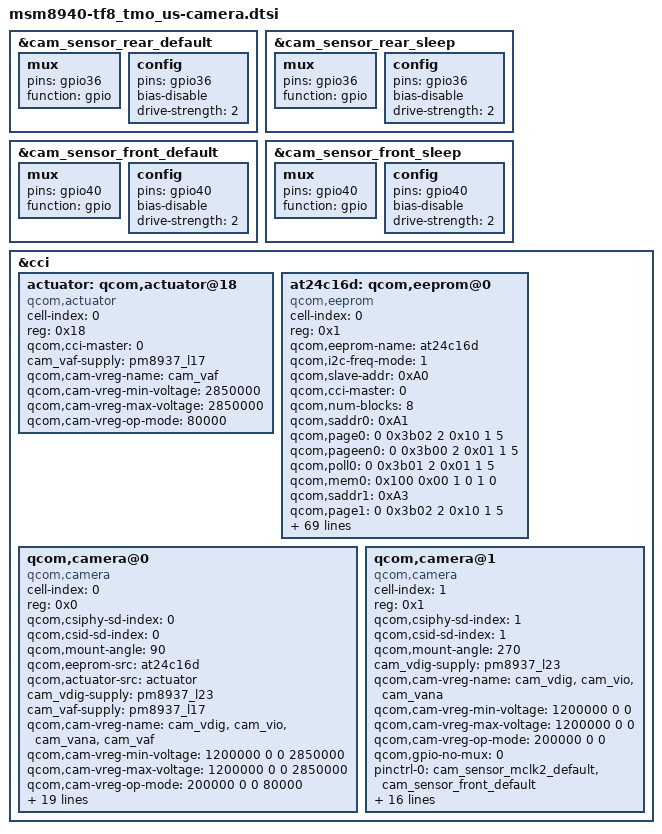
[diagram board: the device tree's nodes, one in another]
/*
 * Copyright (c) 2016, The Linux Foundation. All rights reserved.
 *
 * This program is free software; you can redistribute it and/or modify
 * it under the terms of the GNU General Public License version 2 and
 * only version 2 as published by the Free Software Foundation.
 *
 * This program is distributed in the hope that it will be useful,
 * but WITHOUT ANY WARRANTY; without even the implied warranty of
 * MERCHANTABILITY or FITNESS FOR A PARTICULAR PURPOSE.  See the
 * GNU General Public License for more details.
 */

&cam_sensor_rear_default {
	/* RESET */
	mux {
		pins = "gpio36";
		function = "gpio";
	};

	config {
		pins = "gpio36";
		bias-disable; /* No PULL */
		drive-strength = <2>; /* 2 MA */
	};
};

&cam_sensor_rear_sleep {
	/* RESET */
	mux {
		pins = "gpio36";
		function = "gpio";
	};

	config {
		pins = "gpio36";
		bias-disable; /* No PULL */
		drive-strength = <2>; /* 2 MA */
	};
};

&cam_sensor_front_default {
	/* RESET */
	mux {
		pins = "gpio40";
		function = "gpio";
	};

	config {
		pins = "gpio40";
		bias-disable; /* No PULL */
		drive-strength = <2>; /* 2 MA */
	};
};

&cam_sensor_front_sleep {
	/* RESET */
	mux {
		pins = "gpio40";
		function = "gpio";
	};

	config {
		pins = "gpio40";
		bias-disable; /* No PULL */
		drive-strength = <2>; /* 2 MA */
	};
};

&cci {

	actuator: qcom,actuator@18 {
		cell-index = <0>;
		reg = <0x18>;
		compatible = "qcom,actuator";
		qcom,cci-master = <0>;
		cam_vaf-supply = <&pm8937_l17>;
		qcom,cam-vreg-name = "cam_vaf";
		qcom,cam-vreg-min-voltage = <2850000>;
		qcom,cam-vreg-max-voltage = <2850000>;
		qcom,cam-vreg-op-mode = <80000>;
	};

    at24c16d: qcom,eeprom@0 {
		status = "ok";
		cell-index = <0>;
		reg = <0x1>;
		qcom,eeprom-name = "at24c16d";
		compatible = "qcom,eeprom";
		qcom,i2c-freq-mode = <1>; //fast-mode
		qcom,slave-addr = <0xA0>;
		qcom,cci-master = <0>;
		qcom,num-blocks = <8>;
		qcom,saddr0 = <0xA1>;
		qcom,page0 = <0 0x3b02 2 0x10 1 5>;
		qcom,pageen0 = <0 0x3b00 2 0x01 1 5>;
		qcom,poll0 = <0 0x3b01 2 0x01 1 5>;
		qcom,mem0 = <0x100 0x00 1 0 1 0>;

		qcom,saddr1 = <0xA3>;
		qcom,page1 = <0 0x3b02 2 0x10 1 5>;
		qcom,pageen1 = <0 0x3b00 2 0x01 1 5>;
		qcom,poll1 = <0 0x3b01 2 0x01 1 5>;
		qcom,mem1 = <0x100 0x00 1 0 1 1000>;

		qcom,saddr2 = <0xA5>;
		qcom,page2 = <0 0x3b02 2 0x10 1 5>;
		qcom,pageen2 = <0 0x3b00 2 0x01 1 5>;
		qcom,poll2 = <0 0x3b01 2 0x01 1 5>;
		qcom,mem2 = <0x100 0x00 1 0 1 1000>;

		qcom,saddr3 = <0xA7>;
		qcom,page3 = <0 0x3b02 2 0x10 1 5>;
		qcom,pageen3 = <0 0x3b00 2 0x01 1 5>;
		qcom,poll3 = <0 0x3b01 2 0x01 1 5>;
		qcom,mem3 = <0x100 0x00 1 0 1 0>;

		qcom,saddr4 = <0xA9>;
		qcom,page4 = <0 0x3b02 2 0x10 1 5>;
		qcom,pageen4 = <0 0x3b00 2 0x01 1 5>;
		qcom,poll4 = <0 0x3b01 2 0x01 1 5>;
		qcom,mem4 = <0x100 0x00 1 0 1 0>;

		qcom,saddr5 = <0xAB>;
		qcom,page5 = <0 0x3b02 2 0x10 1 5>;
		qcom,pageen5 = <0 0x3b00 2 0x01 1 5>;
		qcom,poll5 = <0 0x3b01 2 0x01 1 5>;
		qcom,mem5 = <0x100 0x00 1 0 1 0>;

		qcom,saddr6 = <0xAD>;
		qcom,page6 = <0 0x3b02 2 0x10 1 5>;
		qcom,pageen6 = <0 0x3b00 2 0x01 1 5>;
		qcom,poll6 = <0 0x3b01 2 0x01 1 5>;
		qcom,mem6 = <0x100 0x00 1 0 1 0>;

		qcom,saddr7 = <0xAF>;
		qcom,page7 = <0 0x3b02 2 0x10 1 5>;
		qcom,pageen7 = <0 0x3b00 2 0x01 1 5>;
		qcom,poll7 = <0 0x3b01 2 0x01 1 5>;
		qcom,mem7 = <0x100 0x00 1 0 1 0>;

                qcom,cmm-data-support;
                qcom,cmm-data-compressed;
                qcom,cmm-data-offset = <0>;
                qcom,cmm-data-size = <0>;

		cam_vdig-supply = <&pm8937_l23>;
		//cam_vio-supply  = <&pm8937_l6>;
		cam_vaf-supply  = <&pm8937_l17>;
		qcom,cam-vreg-name = "cam_vdig", "cam_vio", "cam_vana", "cam_vaf";
		qcom,cam-vreg-min-voltage = <1200000 0 0 2850000>;
		qcom,cam-vreg-max-voltage = <1200000 0 0 2850000>;
		qcom,cam-vreg-op-mode = <200000 0 0 80000>;
		qcom,gpio-no-mux = <0>;
		pinctrl-names = "cam_default", "cam_suspend";
		pinctrl-0 = <&cam_sensor_mclk0_default &cam_sensor_rear_default>;
		pinctrl-1 = <&cam_sensor_mclk0_sleep &cam_sensor_rear_sleep>;
		gpios = <&tlmm 26 0>, //clk
			<&tlmm 36 0>,  //reset
			<&tlmm 98 0>,  //IOVDD
			<&tlmm 99 0>;  //AVDD
		qcom,gpio-reset = <1>;
		qcom,gpio-vio = <2>;
		qcom,gpio-vana = <3>;
		qcom,gpio-req-tbl-num = <0 1 2 3>;
		qcom,gpio-req-tbl-flags = <1 0 0 0>;
		qcom,gpio-req-tbl-label = "CAMIF_MCLK0",
			"CAM_RESET0", "CAM_IOVDD", "CAM_AVDD";

		qcom,cam-power-seq-type = "sensor_gpio", "sensor_gpio", "sensor_vreg", "sensor_clk", "sensor_gpio";
		qcom,cam-power-seq-val = "sensor_gpio_vio", "sensor_gpio_vana", "cam_vdig", "sensor_cam_mclk", "sensor_gpio_reset";
		qcom,cam-power-seq-cfg-val = <1 0 0 24000000 1 >;
		qcom,cam-power-seq-delay = <1 1 1  2 1>;

		clocks = <&clock_gcc clk_mclk0_clk_src>,
				<&clock_gcc clk_gcc_camss_mclk0_clk>;
		clock-names = "cam_src_clk", "cam_clk";
		qcom,clock-rates = <24000000 0>;
		qcom,sensor-position = <0>;
	};

	qcom,camera@0 {
		cell-index = <0>;
		compatible = "qcom,camera";
		reg = <0x0>;
		qcom,csiphy-sd-index = <0>;
		qcom,csid-sd-index = <0>;
		qcom,mount-angle = <90>;
		//qcom,led-flash-src = <&led_flash0>;
		qcom,eeprom-src = <&at24c16d>;
		qcom,actuator-src = <&actuator>;

		//cam_vana-supply = <&pm8937_l22>;
		cam_vdig-supply = <&pm8937_l23>;
		//cam_vio-supply  = <&pm8937_l6>;
		cam_vaf-supply  = <&pm8937_l17>;
		qcom,cam-vreg-name = "cam_vdig", "cam_vio", "cam_vana", "cam_vaf";
		qcom,cam-vreg-min-voltage = <1200000 0 0 2850000>;
		qcom,cam-vreg-max-voltage = <1200000 0 0 2850000>;
		qcom,cam-vreg-op-mode = <200000 0 0 80000>;
		qcom,gpio-no-mux = <0>;
		pinctrl-names = "cam_default", "cam_suspend";
		pinctrl-0 = <&cam_sensor_mclk0_default &cam_sensor_rear_default>;
		pinctrl-1 = <&cam_sensor_mclk0_sleep &cam_sensor_rear_sleep>;
		gpios = <&tlmm 26 0>, //clk
			<&tlmm 36 0>,  //reset
			<&tlmm 98 0>,  //IOVDD
			<&tlmm 99 0>;  //AVDD
		qcom,gpio-reset = <1>;
		qcom,gpio-vio = <2>;
		qcom,gpio-vana = <3>;
		qcom,gpio-req-tbl-num = <0 1 2 3>;
		qcom,gpio-req-tbl-flags = <1 0 0 0>;
		qcom,gpio-req-tbl-label = "CAMIF_MCLK0",
			"CAM_RESET0", "CAM_IOVDD", "CAM_AVDD";

		qcom,sensor-position = <0>;
		qcom,sensor-mode = <0>;
		qcom,cci-master = <0>;
		status = "ok";
		clocks = <&clock_gcc clk_mclk0_clk_src>,
				<&clock_gcc clk_gcc_camss_mclk0_clk>;
		clock-names = "cam_src_clk", "cam_clk";
		qcom,clock-rates = <24000000 0>;
	};

	qcom,camera@1 {
		cell-index = <1>;
		compatible = "qcom,camera";
		reg = <0x1>;
		qcom,csiphy-sd-index = <1>;
		qcom,csid-sd-index = <1>;
		qcom,mount-angle = <270>;

		//cam_vana-supply = <&pm8937_l22>;
		cam_vdig-supply = <&pm8937_l23>;
		//cam_vio-supply  = <&pm8937_l6>;
		qcom,cam-vreg-name = "cam_vdig", "cam_vio", "cam_vana";
		qcom,cam-vreg-min-voltage = <1200000 0 0>;
		qcom,cam-vreg-max-voltage = <1200000 0 0>;
		qcom,cam-vreg-op-mode = <200000 0 0>;
		qcom,gpio-no-mux = <0>;
		pinctrl-names = "cam_default", "cam_suspend";
		pinctrl-0 = <&cam_sensor_mclk2_default &cam_sensor_front_default>;
		pinctrl-1 = <&cam_sensor_mclk2_sleep &cam_sensor_front_sleep>;
		gpios = <&tlmm 28 0>, //clk
			<&tlmm 40 0>,  //reset
			<&tlmm 98 0>,  //IOVDD
			<&tlmm 99 0>;  //AVDD
		qcom,gpio-reset = <1>;
		qcom,gpio-vio = <2>;
		qcom,gpio-vana = <3>;
		qcom,gpio-req-tbl-num = <0 1 2 3>;
		qcom,gpio-req-tbl-flags = <1 0 0 0>;
		qcom,gpio-req-tbl-label = "CAMIF_MCLK2",
			"CAM_RESET1", "CAM_IOVDD2", "CAM_AVDD2";

		qcom,sensor-position = <1>;
		qcom,sensor-mode = <0>;
		qcom,cci-master = <1>;
		status = "ok";
		clocks = <&clock_gcc clk_mclk2_clk_src>,
				<&clock_gcc clk_gcc_camss_mclk2_clk>;
		clock-names = "cam_src_clk", "cam_clk";
		qcom,clock-rates = <24000000 0>;
	};
};
